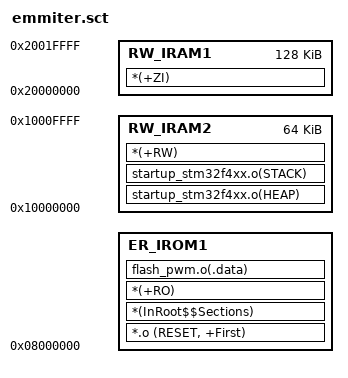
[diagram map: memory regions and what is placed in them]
LR_IROM1 0x8000000 0x100000
{
	ER_IROM1    0x8000000                ;0x8000000
	{
	    *.o (RESET, +First)
        *(InRoot$$Sections)
		;startup_stm32f4xx.o(RO)
		;system_stm32f4xx.o(RO)
		;__main.o(RO)
		;rtentry*.o(RO)
		;sys_stackheap_outer.o
		;libspace.o(RO)
		;libinit*.o(RO)
		;indicate_semi.o(RO)
		;fpinit.o(RO)
		;rtexit*.o
		;libshutdown*.o
		;*(+RO-DATA)
		*(+RO)
		flash_pwm.o(.data)
	}
	
	RW_IRAM2 0x10000000 0x00010000                        ;0x00010000  0x8000 
	{
		startup_stm32f4xx.o(HEAP)
		startup_stm32f4xx.o(STACK)
		*(+RW)
		
	}
	
	RW_IRAM1 0x20000000 0x00020000
	{
		;*(+RO)
		*(+ZI)
	}
	
	;ARM_LIB_STACKHEAP 0x10008000 EMPTY 0x8000
	;{}
	
}
	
